# STM32L562 register map
File version: 1.0
CPU: CM33 r0p1, little endian, MPU, FPU, 3 interrupt priority bits
Registers are 32-bit, read-write, reset 0x0 unless marked. A register's access mark holds for its fields unless they carry their own. Offsets are from the block's base; [hi:lo] are bit positions; {n}, {i} and the like mark numbered series.

## AES — Advanced encryption standard hardware accelerator 1
Base 0x420C0000
Same registers: SEC_AES 0x520C0000
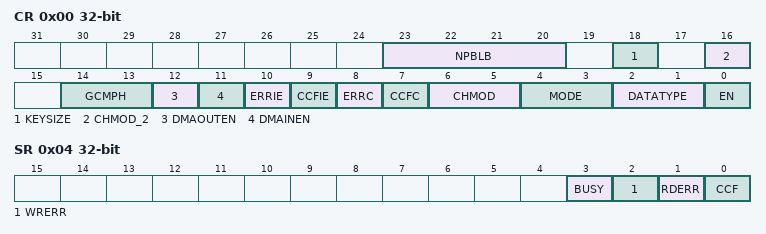
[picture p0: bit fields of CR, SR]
0x00 CR — control register
  [23:20] NPBLB — Number of padding bytes in last block of payload
  [18] KEYSIZE — Key size selection
    0=AES128 (128); 1=AES256 (256)
  [16] CHMOD_2 — AES chaining mode Bit2
    0=CHMOD (Mode as per CHMOD (ECB, CBC, CTR, GCM)); 1=CCM (Counter with CBC-MAC (CCM) - CHMOD must be 0 (ECB))
  [14:13] GCMPH — Used only for GCM, CCM and GMAC algorithms and has no effect when other algorithms are selected
    0=Init phase; 1=Header phase; 2=Payload phase; 3=Final Phase
  [12] DMAOUTEN — Enable DMA management of data output phase
    0=Disable DMA Output; 1=Enabled DMA Output
  [11] DMAINEN — Enable DMA management of data input phase
    0=Disable DMA Input; 1=Enable DMA Input
  [10] ERRIE — Error interrupt enable
    0=Disabled (Disable (mask) error interrupt); 1=Enabled (Enable error interrupt)
  [9] CCFIE — CCF flag interrupt enable
    0=Disabled (Disable (mask) CCF interrupt); 1=Enabled (Enable CCF interrupt)
  [8] ERRC — Error clear
    on write: 1=Clear RDERR and WRERR flags
  [7] CCFC — Computation Complete Flag Clear
    on write: 1=Clear computation complete flag
  [6:5] CHMOD — AES chaining mode selection Bit1 Bit0
    0=ECB (Electronic codebook (ECB) / Counter with CBC-MAC (CCM) if CHMOD2 is 1); 1=CBC (Cipher-block chaining (CBC)); 2=CTR (Counter mode (CTR)); 3=GCM (Galois counter mode (GCM) and Galois message authentication code (GMAC))
  [4:3] MODE — AES operating mode
    0=Mode 1: encryption; 1=Mode 2: key derivation (or key preparation for ECB/CBC decryption); 2=Mode 3: decryption; 3=Mode 4: key derivation then single decryption
  [2:1] DATATYPE — Data type selection (for data in and data out to/from the cryptographic block)
    0=None (Word); 1=Half-word (16-bit); 2=Byte (8-bit); 3=Bit
  [0] EN — AES enable
    0=Disabled (Disable AES); 1=Enabled (Enable AES)
0x04 SR ro — status register
  [3] BUSY — Busy flag
    0=Idle; 1=Busy
  [2] WRERR — Write error flag
    0=NoError (Write error not detected); 1=Error (Write error detected)
  [1] RDERR — Read error flag
    0=NoError (Read error not detected); 1=Error (Read error detected)
  [0] CCF — Computation complete flag
    0=Complete (Computation complete); 1=NotComplete (Computation not complete)
0x08 DINR — data input register
  [31:0] DIN — Data Input Register
0x0C DOUTR ro — data output register
  [31:0] DOUT — Data output register
0x10 KEYR0 wo — key register 0
  [31:0] KEY — Cryptographic key, bits[31:0]
{0x10+4i} KEYR{i} wo (i=1..3) — key register {i}
  [31:0] KEY — Cryptographic key, bits [{32i+31}:{32i}])
0x20 IVR0 — initialization vector register 0
  [31:0] IVI — initialization vector register (LSB IVR [31:0])
0x24 IVR1 — initialization vector register 1
  [31:0] IVI — Initialization Vector Register (IVR [63:32])
0x28 IVR2 — initialization vector register 2
  [31:0] IVI — Initialization Vector Register (IVR [95:64])
0x2C IVR3 — initialization vector register 3
  [31:0] IVI — Initialization Vector Register (MSB IVR [127:96])
{0x20+4i} KEYR{i} wo (i=4..7) — key register {i}
  [31:0] KEY — Cryptographic key, bits [{32i+31}:{32i}])
{0x40+4i} SUSP{i}R (i=0..7) — AES suspend register {i}
  [31:0] SUSP

## COMP — Comparator
Base 0x40010200
Same registers: SEC_COMP 0x50010200
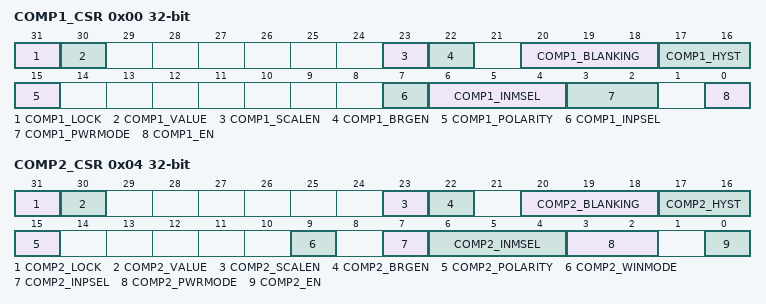
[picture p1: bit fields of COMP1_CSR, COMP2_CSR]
0x00 COMP1_CSR access per field — Comparator 1 control and status register
  [31] COMP1_LOCK wo — COMP1_CSR register lock bit
  [30] COMP1_VALUE ro — Comparator 1 output status bit
  [23] COMP1_SCALEN rw — Voltage scaler enable bit
  [22] COMP1_BRGEN rw — Scaler bridge enable
  [20:18] COMP1_BLANKING rw — Comparator 1 blanking source selection bits
  [17:16] COMP1_HYST rw — Comparator 1 hysteresis selection bits
  [15] COMP1_POLARITY rw — Comparator 1 polarity selection bit
  [7] COMP1_INPSEL rw — Comparator1 input plus selection bit
  [6:4] COMP1_INMSEL rw — Comparator 1 Input Minus connection configuration bit
  [3:2] COMP1_PWRMODE rw — Power Mode of the comparator 1
  [0] COMP1_EN rw — Comparator 1 enable bit
0x04 COMP2_CSR access per field — Comparator 2 control and status register
  [31] COMP2_LOCK wo — COMP2_CSR register lock bit
  [30] COMP2_VALUE ro — Comparator 2 output status bit
  [23] COMP2_SCALEN rw — Voltage scaler enable bit
  [22] COMP2_BRGEN rw — Scaler bridge enable
  [20:18] COMP2_BLANKING rw — Comparator 2 blanking source selection bits
  [17:16] COMP2_HYST rw — Comparator 2 hysteresis selection bits
  [15] COMP2_POLARITY rw — Comparator 2 polarity selection bit
  [9] COMP2_WINMODE rw — Windows mode selection bit
  [7] COMP2_INPSEL rw — Comparator 2 Input Plus connection configuration bit
  [6:4] COMP2_INMSEL rw — Comparator 2 Input Minus connection configuration bit
  [3:2] COMP2_PWRMODE rw — Power Mode of the comparator 2
  [0] COMP2_EN rw — Comparator 2 enable bit
